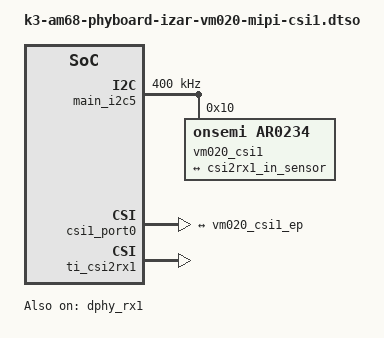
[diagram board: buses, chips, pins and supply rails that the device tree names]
// SPDX-License-Identifier: GPL-2.0
/*
 * Copyright (C) 2023 PHYTEC Messtechnik GmbH
 * Author: Stefan Riedmüller <s.riedmueller@phytec.de>
 */

/dts-v1/;
/plugin/;

#include <dt-bindings/gpio/gpio.h>

&{/} {
	clk_cam_csi1: clk-cam-csi1 {
		compatible = "fixed-clock";
		#clock-cells = <0>;
		clock-frequency = <27000000>;
	};
};

&main_i2c5 {
	clock-frequency = <400000>;
	#address-cells = <1>;
	#size-cells = <0>;
	status = "okay";

	vm020_csi1: vm020-csi1@10 {
		compatible = "onsemi,ar0234";
		reg = <0x10>;

		clock-names = "ext";
		clocks = <&clk_cam_csi1>;

		port {
			vm020_csi1_ep: endpoint {
				remote-endpoint = <&csi2rx1_in_sensor>;
				data-lanes = <1 2 3 4>;
				clock-lanes = <0>;
				clock-noncontinuous = <1>;
				bus-type = <4>; /* MIPI_CSI2_DPHY */
				link-frequencies = /bits/ 64 <450000000>;
			};
		};
	};
};

&csi1_port0 {
	status = "okay";

	csi2rx1_in_sensor: endpoint {
		remote-endpoint = <&vm020_csi1_ep>;
		bus-type = <4>; /* CSI2 DPHY. */
		clock-lanes = <0>;
		data-lanes = <1 2 3 4>;
	};
};

&dphy_rx1 {
	status = "okay";
};

&ti_csi2rx1 {
	status = "okay";
};
